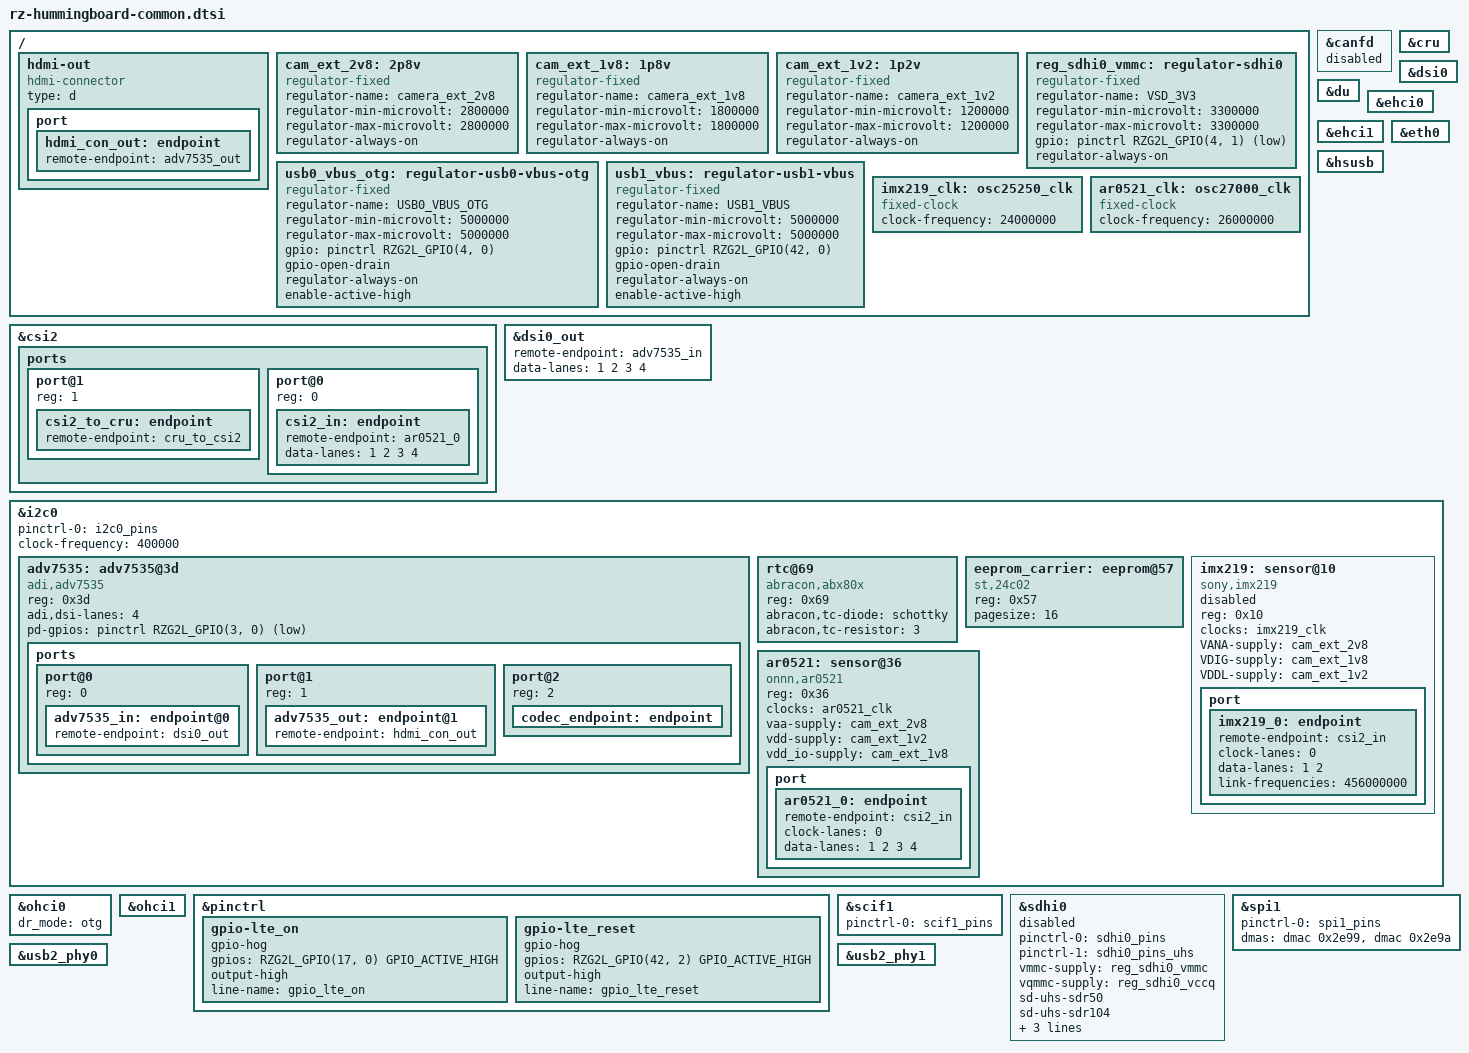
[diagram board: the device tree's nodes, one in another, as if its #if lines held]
// SPDX-License-Identifier: (GPL-2.0-only OR BSD-2-Clause)
/*
 * Device Tree Source for the RZ Solidrun HummingBoards
 *
 * Copyright (C) 2023 SolidRun Ltd.
 */

#include <dt-bindings/gpio/gpio.h>
#include <dt-bindings/pinctrl/rzg2l-pinctrl.h>

/ {
	hdmi-out {
		compatible = "hdmi-connector";
		type = "d";

		port {
			hdmi_con_out: endpoint {
			remote-endpoint = <&adv7535_out>;
			};
		};
	};

	cam_ext_2v8: 2p8v {
		compatible = "regulator-fixed";
		regulator-name = "camera_ext_2v8";
		regulator-min-microvolt = <2800000>;
		regulator-max-microvolt = <2800000>;
		regulator-always-on;
	};

	cam_ext_1v8: 1p8v {
		compatible = "regulator-fixed";
		regulator-name = "camera_ext_1v8";
		regulator-min-microvolt = <1800000>;
		regulator-max-microvolt = <1800000>;
		regulator-always-on;
	};

	cam_ext_1v2: 1p2v {
		compatible = "regulator-fixed";
		regulator-name = "camera_ext_1v2";
		regulator-min-microvolt = <1200000>;
		regulator-max-microvolt = <1200000>;
		regulator-always-on;
	};

	reg_sdhi0_vmmc: regulator-sdhi0 {
		compatible = "regulator-fixed";
		regulator-name = "VSD_3V3";
		regulator-min-microvolt = <3300000>;
		regulator-max-microvolt = <3300000>;
		gpio = <&pinctrl RZG2L_GPIO(4, 1) GPIO_ACTIVE_LOW>;
		regulator-always-on;
	};

	usb0_vbus_otg: regulator-usb0-vbus-otg {
		compatible = "regulator-fixed";
		regulator-name = "USB0_VBUS_OTG";
		regulator-min-microvolt = <5000000>;
		regulator-max-microvolt = <5000000>;
		gpio = <&pinctrl RZG2L_GPIO(4, 0) GPIO_ACTIVE_HIGH>;
		gpio-open-drain;
		regulator-always-on;
		enable-active-high;
	};

	usb1_vbus: regulator-usb1-vbus {
		compatible = "regulator-fixed";
		regulator-name = "USB1_VBUS";
		regulator-min-microvolt = <5000000>;
		regulator-max-microvolt = <5000000>;
		gpio = <&pinctrl RZG2L_GPIO(42, 0) GPIO_ACTIVE_HIGH>;
		gpio-open-drain;
		regulator-always-on;
		enable-active-high;
	};

	imx219_clk: osc25250_clk {
		compatible = "fixed-clock";
		#clock-cells = <0>;
		clock-frequency = <24000000>;
	};

	ar0521_clk: osc27000_clk {
		compatible = "fixed-clock";
		#clock-cells = <0>;
		clock-frequency = <26000000>;
	};
};

&canfd {
	/delete-property/ pinctrl-0;
	/delete-property/ pinctrl-names;
	status = "disabled";
};

&cru {
	status = "okay";
};

&csi2 {
	status = "okay";
	ports {
		#address-cells = <1>;
		#size-cells = <0>;

		port@1 {
			reg = <1>;

			csi2_to_cru: endpoint {
				remote-endpoint = <&cru_to_csi2>;
			};
		};

		port@0 {
			reg = <0>;

			csi2_in: endpoint {
				remote-endpoint = <&ar0521_0>;
				data-lanes = <1 2 3 4>;
			};
		};
	};
};

&dsi0 {
	status = "okay";
};

&dsi0_out {
	remote-endpoint = <&adv7535_in>;
	data-lanes = <1 2 3 4>;
};

&du {
	status = "okay";
};

&ehci0 {
	status = "okay";
};

&ehci1 {
	status = "okay";
};

&eth0 {
	status = "okay";
};

&hsusb {
	status = "okay";
};

&i2c0 {
	pinctrl-0 = <&i2c0_pins>;
	pinctrl-names = "default";
	clock-frequency = <400000>;
	status = "okay";

	adv7535: adv7535@3d {
		compatible = "adi,adv7535";
		reg = <0x3d>;
		adi,dsi-lanes = <4>;
		pd-gpios = <&pinctrl RZG2L_GPIO(3, 0) GPIO_ACTIVE_LOW>; // ADV_PD / DSI_EN J9-34 / P4_0
		/*
		 * With interrupts enabled and hdmi connected during boot,
		 * rzg2l_mipi_dsi_enable never happens and display receives no signal.
		 * Re-enable once issue has been resolved.
		 *
		 * interrupt-parent = <&pinctrl>;
		 * interrupts = <RZG2L_GPIO(9, 1) IRQ_TYPE_EDGE_FALLING>; // DSI_TS_nINT J5001-43 P9_1
		 */
		status = "okay";

		ports {
			#address-cells = <1>;
			#size-cells = <0>;

			port@0 {
				reg = <0>;
				adv7535_in: endpoint@0 {
					remote-endpoint = <&dsi0_out>;
				};
			};

			port@1 {
				reg = <1>;
				adv7535_out: endpoint@1 {
					remote-endpoint = <&hdmi_con_out>;
				};
			};

			port@2 {
				reg = <2>;
				codec_endpoint: endpoint {
					/* Audio signals not connected. */
				};
			};
		};
	};

	rtc@69 {
		compatible = "abracon,abx80x";
		reg = <0x69>;
		abracon,tc-diode = "schottky";
		abracon,tc-resistor = <3>;
	};

	eeprom_carrier: eeprom@57 {
		compatible = "st,24c02", "atmel,24c02";
		reg = <0x57>;
		pagesize = <16>;
	};


	imx219: sensor@10 {
		compatible = "sony,imx219";
		reg = <0x10>;
		clocks = <&imx219_clk>;
		clock-names = "extclk";
		VANA-supply = <&cam_ext_2v8>;
		VDIG-supply = <&cam_ext_1v8>;
		VDDL-supply = <&cam_ext_1v2>;
		status = "disabled";

		port {
			imx219_0: endpoint {
				remote-endpoint = <&csi2_in>;
				clock-lanes = <0>;
				data-lanes = <1 2>;
				link-frequencies = /bits/ 64 <456000000>;
			};
		};
	};

	ar0521: sensor@36 {
		compatible = "onnn,ar0521";
		reg = <0x36>;
		clocks = <&ar0521_clk>;
		clock-names = "extclk";
		vaa-supply = <&cam_ext_2v8>;
		vdd-supply = <&cam_ext_1v2>;
		vdd_io-supply = <&cam_ext_1v8>;

		port {
			ar0521_0: endpoint {
				remote-endpoint = <&csi2_in>;
				clock-lanes = <0>;
				data-lanes = <1 2 3 4>;
			};
		};
	};
};

&ohci0 {
	dr_mode = "otg";
	status = "okay";
};

&ohci1 {
	status = "okay";
};

&pinctrl {
	gpio-lte_on {
		gpio-hog;
		gpios = <RZG2L_GPIO(17, 0) GPIO_ACTIVE_HIGH>;
		output-high;
		line-name = "gpio_lte_on";
	};

	gpio-lte_reset {
		gpio-hog;
		gpios = <RZG2L_GPIO(42, 2) GPIO_ACTIVE_HIGH>;
		output-high;
		line-name = "gpio_lte_reset";
	};
};

&scif1 {
	pinctrl-0 = <&scif1_pins>;
	pinctrl-names = "default";
	//uart-has-rtscts;
	status = "okay";
};

/* uSD */
&sdhi0 {
#if (!SW_SD0_DEV_SEL)
	pinctrl-0 = <&sdhi0_pins>;
	pinctrl-1 = <&sdhi0_pins_uhs>;
	pinctrl-names = "default", "state_uhs";

	vmmc-supply = <&reg_sdhi0_vmmc>;
	vqmmc-supply = <&reg_sdhi0_vccq>;
	sd-uhs-sdr50;
	sd-uhs-sdr104;
	bus-width = <4>;
	max-frequency = <50000000>; /* 50MiB */
	status = "disabled";
#endif
	cd-gpios = <&pinctrl RZG2L_GPIO(47, 0) GPIO_ACTIVE_LOW>;
};

&spi1 {
	pinctrl-0 = <&spi1_pins>;
	pinctrl-names = "default";
	dmas = <&dmac 0x2e99>, <&dmac 0x2e9a>;
	dma-names = "tx", "rx";
	status = "okay";
};

&usb2_phy0 {
	status = "okay";
};

&usb2_phy1 {
	status = "okay";
};
